# dp_aux_hpd_model: IP-XACT component
VLNV IcronTechnologies:IcronTechnologies:dp_aux_hpd_model:1.0

## Parameters
addr_width = 8
bus_width = 32

## Bus interfaces (logical=physical port)
default_map: slave AGNISYS:AGNISYS:APB:1.0, memory map dp_aux_hpdmap
  pclk=pclk, presetn=presetn, psel=psel, penable=penable, pwrite=pwrite, pprot=pprot, pstrb=pstrb, pwdata=pwdata, paddr=paddr, pready=pready, prdata=prdata, pslverr=pslverr

## Ports
in pclk
in presetn
in psel
in penable
in pwrite
in pprot[2:0]
in pstrb[(bus_width div 8 )-1:0]
in pwdata[bus_width -1:0]
in paddr[addr_width -1:0]
out pready
out prdata[bus_width -1:0]
out pslverr
out dp_aux_hpd_regsversion_major_r[7:0]
out dp_aux_hpd_regsversion_minor_r[7:0]
out dp_aux_hpd_regsversion_patch_r[7:0]
in dp_aux_hpd_regsaux_status_aux_sense_p_in_debounce_in
in dp_aux_hpd_regsaux_status_aux_sense_p_in_debounce_in_enb
in dp_aux_hpd_regsaux_status_aux_sense_n_in_debounce_in
in dp_aux_hpd_regsaux_status_aux_sense_n_in_debounce_in_enb
in dp_aux_hpd_regsaux_status_aux_sense_p_in_in
in dp_aux_hpd_regsaux_status_aux_sense_p_in_in_enb
in dp_aux_hpd_regsaux_status_aux_sense_n_in_in
in dp_aux_hpd_regsaux_status_aux_sense_n_in_in_enb
in dp_aux_hpd_regsaux_status_sent_defer_cnt_in[3:0]
in dp_aux_hpd_regsaux_status_sent_defer_cnt_in_enb
in dp_aux_hpd_regsaux_status_response_timeout_cnt_in[16:0]
in dp_aux_hpd_regsaux_status_response_timeout_cnt_in_enb
out dp_aux_hpd_regsaux_ctrl{n}_enb (n=1..3)
out dp_aux_hpd_regsaux_ctrl1_reply_timer_r[12:0]
out dp_aux_hpd_regsaux_ctrl1_response_timer_r[12:0]
out dp_aux_hpd_regsaux_ctrl2_pre_charge_length_r[4:0]
out dp_aux_hpd_regsaux_ctrl3_dp_aux_hpd_clk_freq_r[7:0]
in dp_aux_hpd_regsaux_rx_rx_flag_in
in dp_aux_hpd_regsaux_rx_rx_flag_in_enb
in dp_aux_hpd_regsaux_rx_rx_data_in[7:0]
in dp_aux_hpd_regsaux_rx_rx_data_in_enb
out dp_aux_hpd_regsaux_rx_rx_data_rd_pulse
out dp_aux_hpd_regsaux_tx_enb
out dp_aux_hpd_regsaux_tx_go_bit_r
in dp_aux_hpd_regsaux_tx_go_bit_hw_clear
out dp_aux_hpd_regsaux_tx_tx_flag_r
out dp_aux_hpd_regsaux_tx_tx_data_r[7:0]
out dp_aux_hpd_regsregaux_tx_tx_data_wr_pulse
in dp_aux_hpd_regshpd_status_hpd_line_out_in
in dp_aux_hpd_regshpd_status_hpd_line_out_in_enb
in dp_aux_hpd_regshpd_status_hpd_line_in_debounce_in
in dp_aux_hpd_regshpd_status_hpd_line_in_debounce_in_enb
in dp_aux_hpd_regshpd_status_hpd_line_in_in
in dp_aux_hpd_regshpd_status_hpd_line_in_in_enb
out dp_aux_hpd_regshpd_ctrl_enb
out dp_aux_hpd_regshpd_ctrl_hpd_low_r
in dp_aux_hpd_regshpd_ctrl_hpd_low_hw_clear
out dp_aux_hpd_regshpd_ctrl_hpd_high_r
in dp_aux_hpd_regshpd_ctrl_hpd_high_hw_clear
out dp_aux_hpd_regshpd_ctrl_hpd_replug_r
in dp_aux_hpd_regshpd_ctrl_hpd_replug_hw_clear
out dp_aux_hpd_regshpd_ctrl_hpd_irq_r
in dp_aux_hpd_regshpd_ctrl_hpd_irq_hw_clear
out dp_aux_hpd_regshpd_timer{n}_enb (n=1..3)
out dp_aux_hpd_regshpd_timer1_hpd_irq_to_irq_min_gap_r[5:0]
out dp_aux_hpd_regshpd_timer1_hpd_irq_pulse_width_r[3:0]
out dp_aux_hpd_regshpd_timer2_hpd_replug_pulse_width_r[7:0]
out dp_aux_hpd_regshpd_timer3_hpd_irq_rising_detect_r[5:0]
out dp_aux_hpd_regshpd_timer3_hpd_irq_falling_detect_r[3:0]
out dp_aux_hpd_regshpd_timer3_hpd_aux_debounce_period_r[10:0]
out dp_aux_hpd_regshpd_rise_det_enb
in dp_aux_hpd_regshpd_rise_det_cnt_in[7:0]
in dp_aux_hpd_regshpd_rise_det_cnt_in_enb
out dp_aux_hpd_regshpd_rise_det_rst_r
out dp_aux_hpd_regshpd_rise_det_ctrl_r
out dp_aux_hpd_regshpd_fall_det_enb
in dp_aux_hpd_regshpd_fall_det_cnt_in[7:0]
in dp_aux_hpd_regshpd_fall_det_cnt_in_enb
out dp_aux_hpd_regshpd_fall_det_rst_r
out dp_aux_hpd_regshpd_fall_det_ctrl_r
out dp_aux_hpd_regsdp_source_connect_det_enb
in dp_aux_hpd_regsdp_source_connect_det_cnt_in[7:0]
in dp_aux_hpd_regsdp_source_connect_det_cnt_in_enb
out dp_aux_hpd_regsdp_source_connect_det_rst_r
out dp_aux_hpd_regsdp_source_connect_det_ctrl_r
out dp_aux_hpd_regsdp_source_disconnect_det_enb
in dp_aux_hpd_regsdp_source_disconnect_det_cnt_in[7:0]
in dp_aux_hpd_regsdp_source_disconnect_det_cnt_in_enb
out dp_aux_hpd_regsdp_source_disconnect_det_rst_r
out dp_aux_hpd_regsdp_source_disconnect_det_ctrl_r

## Address spaces and blocks
dp_aux_hpdmap.dp_aux_hpd: base 0x000, range 0x100, width 32

## Registers
Registers are 32-bit, read-write, reset 0x0 unless marked. A register's access mark holds for its fields unless they carry their own. Offsets are from the block's base; lines under a group give offsets from that group; [hi:lo] are bit positions; {n}, {i} and the like mark numbered series; 'fields as' and 'values as' point back to an identical list; <NAME> marks a mode.

## dp_aux_hpdmap.dp_aux_hpd — DP aux hpd
Base 0x00000000
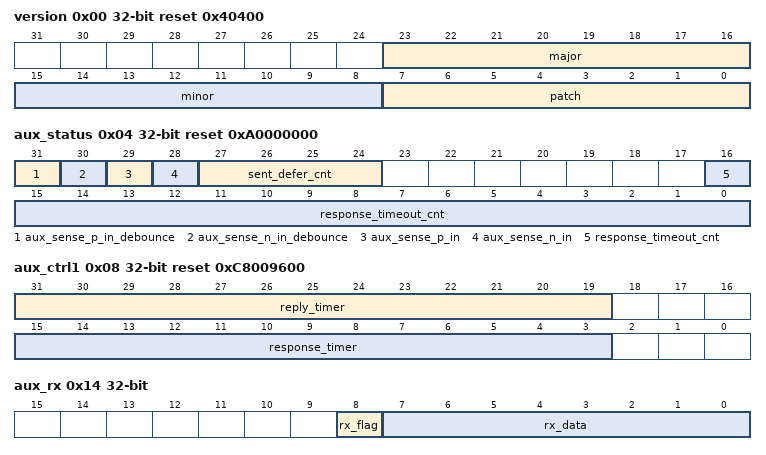
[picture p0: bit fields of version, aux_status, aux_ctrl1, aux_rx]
0x00 version ro reset 0x40400
  [23:16] major — Major version
  [15:8] minor — Minor version
  [7:0] patch — Patch version
0x04 aux_status ro reset 0xA0000000 — Error bits for source/sink and misc status bits
  [31] aux_sense_p_in_debounce — Aux + line status after de-bouncing 1: DP source device is not connected 0: DP source device is connected
  [30] aux_sense_n_in_debounce — Aux - line status after de-bouncing 1: DP source device provides power on DP_PWR pin 0: DP source device does not provide power for sink
  [29] aux_sense_p_in — Aux + line status 1: DP source device is not connected 0: DP source device is connected
  [28] aux_sense_n_in — Aux - line status 1: DP source device provides power on DP_PWR pin 0: DP source device does not provide power for sink
  [27:24] sent_defer_cnt — Number of sent defers
  [16:0] response_timeout_cnt — Response timer value
0x08 aux_ctrl1 reset 0xC8009600 — Aux control 1
  [31:19] reply_timer — 400us response timer setting in 0.0625 us step
  [15:3] response_timer — 300us response timer setting in 0.0625 us step
0x0C aux_ctrl2 reset 0x1F0000 — Aux control 2
  [20:16] pre_charge_length — Number of Zeroes in pre-charge period (register value + 1)
0x10 aux_ctrl3 reset 0x4B — Aux control 3
  [7:0] dp_aux_hpd_clk_freq — DP Aux and Hpd clock frequency in Mhz
0x14 aux_rx ro — Aux receiver data and flag register
  [8] rx_flag — High in EOP cycle
  [7:0] rx_data — aux received data
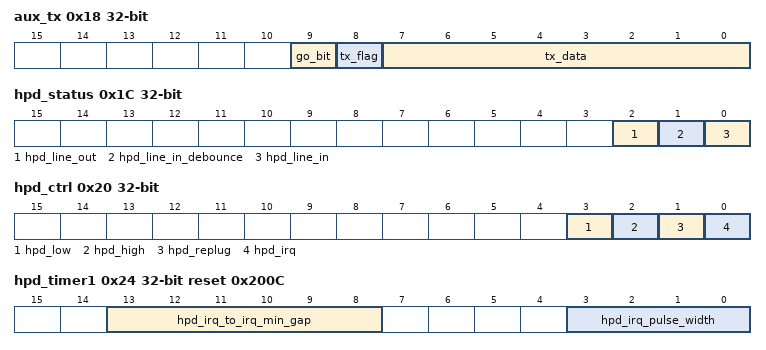
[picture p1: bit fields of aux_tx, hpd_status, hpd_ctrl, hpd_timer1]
0x18 aux_tx access per field — Aux transmitter data and flag register
  [9] go_bit rw — Set high to assert aux go_bit (source or sink)
  [8] tx_flag wo — High in EOP cycle
  [7:0] tx_data wo — aux transmit data
0x1C hpd_status ro — Error bits for source/sink and misc status bits
  [2] hpd_line_out — HPD line out status
  [1] hpd_line_in_debounce — HPD line in after de-bouncing status
  [0] hpd_line_in — HPD line in status
0x20 hpd_ctrl — HPD generator control bits
  [3] hpd_low — Set high to generate LOW on HPD
  [2] hpd_high — Set high to generate HIGH on HPD
  [1] hpd_replug — Set high to generate a long pulse on HPD
  [0] hpd_irq — Set high to generate IRQ pulse on HPD
0x24 hpd_timer1 reset 0x200C — Aux control
  [13:8] hpd_irq_to_irq_min_gap — 2048 us hpd_irq to hpd_irq minimum gap setting in 64 us step step (spec indicates minimum of 2ms)
  [3:0] hpd_irq_pulse_width — 768 us hpd_irq pulse setting in 64 us step (spec indicates 0.5ms to 1ms)
0x28 hpd_timer2 reset 0x9C — Aux control
  [7:0] hpd_replug_pulse_width — 9.984us hpd_replug pulse setting in 64 us step (spec indicates 2ms to 100ms)
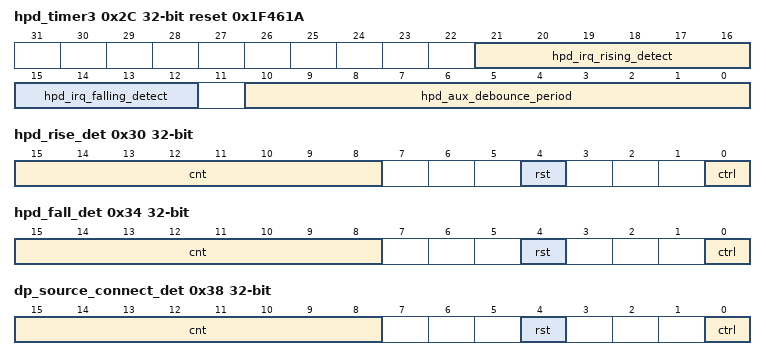
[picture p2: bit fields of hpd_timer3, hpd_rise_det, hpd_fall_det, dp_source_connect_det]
0x2C hpd_timer3 reset 0x1F461A — Aux control
  [21:16] hpd_irq_rising_detect — Rising pulse 2ms detection of hpd_irq (in 64us steps)
  [15:12] hpd_irq_falling_detect — Falling pulse 0.25ms detection of hpd_irq (in 64us steps)
  [10:0] hpd_aux_debounce_period — De-bounce period of 100ms for hpd and aux sense signals (in 64us steps)
0x30 hpd_rise_det access per field — HPD line falling edge counter logic
  [15:8] cnt ro — Count value. It saturates at 8'd255.
  [4] rst rw — Write 1 and then 0 to reset the counter.
  [0] ctrl rw — 1'b1: Start counter 1'b0: Stop counter
0x34 hpd_fall_det access per field — HPD line falling edge counter logic
  fields as hpd_rise_det
0x38 dp_source_connect_det access per field — DP source connect detect counter logic
  fields as hpd_rise_det
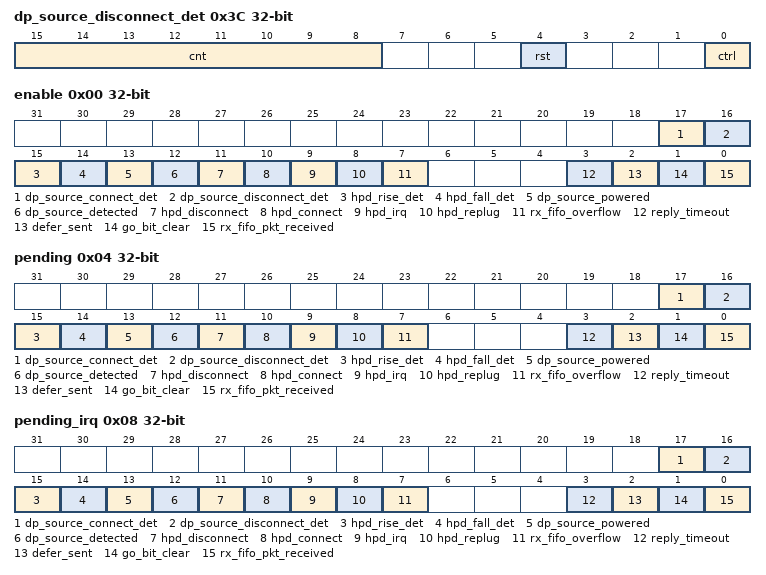
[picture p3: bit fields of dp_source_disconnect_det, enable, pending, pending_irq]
0x3C dp_source_disconnect_det access per field — DP source disconnect detect counter logic
  fields as hpd_rise_det
0x40 irq group — aux_hpd Interrupt register group
  0x00 enable — Interrupt Enable register - Write 1 to enable, 0 to mask an interrupt
    [17] dp_source_connect_det — Set high to enable dp_source_connect_det interrupt
    [16] dp_source_disconnect_det — Set high to enable dp_source_disconnect_det interrupt
    [15] hpd_rise_det — Set high to enable hpd_rise_det interrupt
    [14] hpd_fall_det — Set high to enable hpd_fall_det interrupt
    [13] dp_source_powered — Set high to enable dp_source_powered interrupt
    [12] dp_source_detected — Set high to enable dp_source_detected interrupt
    [11] hpd_disconnect — Set high to enable hpd_disconnect interrupt
    [10] hpd_connect — Set high to enable hpd_connect interrupt
    [9] hpd_irq — Set high to enable hpd_irq interrupt
    [8] hpd_replug — Set high to enable hpd_replug interrupt
    [7] rx_fifo_overflow — Set high to enable rx_fifo_overflow
    [3] reply_timeout — Set high to enable reply timeout interrupt
    [2] defer_sent — Set high to enable defer_sent interrupt
    [1] go_bit_clear — Set high to enable go_bit_clear interrupt
    [0] rx_fifo_pkt_received — Set high to enable rx_fifo_pkt_received interrupt
  0x04 pending — Interrupt Pending register - This indicates which enabled interrupts have triggered, Write 1 to clear
    [17] dp_source_connect_det write-1-clears — Registered dp_source_connect_det
    [16] dp_source_disconnect_det write-1-clears — Registered dp_source_disconnect_det
    [15] hpd_rise_det write-1-clears — Registered hpd_rise_det
    [14] hpd_fall_det write-1-clears — Registered hpd_fall_det
    [13] dp_source_powered write-1-clears — Registered dp_source_powered
    [12] dp_source_detected write-1-clears — Registered dp_source_detected
    [11] hpd_disconnect write-1-clears — Registered hpd_disconnect
    [10] hpd_connect write-1-clears — Registered hpd_connect
    [9] hpd_irq write-1-clears — Registered hpd_irq
    [8] hpd_replug write-1-clears — Registered hpd_replug
    [7] rx_fifo_overflow write-1-clears — Registered rx_fifo_overflow
    [3] reply_timeout write-1-clears — Registered reply timeout
    [2] defer_sent write-1-clears — Registered defer_sent
    [1] go_bit_clear write-1-clears — Registered go_bit_clear
    [0] rx_fifo_pkt_received write-1-clears — Registered rx_fifo_pkt_received
  0x08 pending_irq ro — Interrupt Pending register - This indicates which enabled interrupts have triggered, Write 1 to clear
    [17] dp_source_connect_det — Registered dp_source_connect_det
    [16] dp_source_disconnect_det — Registered dp_source_disconnect_det
    [15] hpd_rise_det — Registered hpd_rise_det
    [14] hpd_fall_det — Registered hpd_fall_det
    [13] dp_source_powered — Registered dp_source_powered
    [12] dp_source_detected — Registered dp_source_detected
    [11] hpd_disconnect — Registered hpd_disconnect
    [10] hpd_connect — Registered hpd_connect
    [9] hpd_irq — Registered hpd_irq
    [8] hpd_replug — Registered hpd_replug
    [7] rx_fifo_overflow — Registered rx_fifo_overflow
    [3] reply_timeout — Registered reply timeout
    [2] defer_sent — Registered defer_sent
    [1] go_bit_clear — Registered go_bit_clear
    [0] rx_fifo_pkt_received — Registered rx_fifo_pkt_received
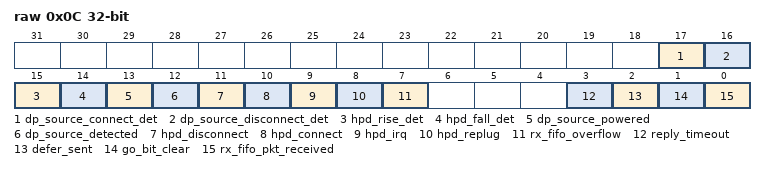
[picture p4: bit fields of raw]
  0x0C raw ro — This register contains the registered state of interrupt signals
    [17] dp_source_connect_det — Current status of dp_source_connect_det
    [16] dp_source_disconnect_det — Current status of dp_source_disconnect_det
    [15] hpd_rise_det — Current status of hpd_rise_det
    [14] hpd_fall_det — Current status of hpd_fall_det
    [13] dp_source_powered — Current status of dp_source_powered
    [12] dp_source_detected — Current status of dp_source_detected
    [11] hpd_disconnect — Current status of hpd_disconnect
    [10] hpd_connect — Current status of hpd_connect
    [9] hpd_irq — Current status of hpd_irq
    [8] hpd_replug — Current status of hpd_replug
    [7] rx_fifo_overflow — Current status of rx_fifo_overflow
    [3] reply_timeout — Current status of reply timeout
    [2] defer_sent — Current status of defer_sent
    [1] go_bit_clear — Current status of go_bit_clear
    [0] rx_fifo_pkt_received — Current status of rx_fifo_pkt_received
